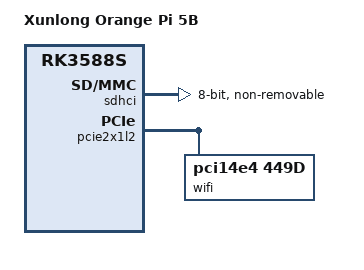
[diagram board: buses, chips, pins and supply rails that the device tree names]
// SPDX-License-Identifier: (GPL-2.0+ OR MIT)

/dts-v1/;

#include "rk3588s-orangepi-5.dts"

/ {
	model = "Xunlong Orange Pi 5B";
	compatible = "xunlong,orangepi-5b", "rockchip,rk3588s";

	aliases {
		mmc0 = &sdmmc;
		mmc1 = &sdhci;
	};
};

&sdhci {
	bus-width = <8>;
	no-sdio;
	no-sd;
	non-removable;
	/* HS400 doesn't work properly -> https://github.com/torvalds/linux/commit/cee572756aa2cb46e959e9797ad4b730b78a050b */
	mmc-hs200-1_8v;
	max-frequency = <200000000>;
	status = "okay";
};

&sfc {
	status = "disabled";
};

&pcie2x1l2 {
	pcie@0,0 {
		reg = <0x400000 0 0 0 0>;
		#address-cells = <3>;
		#size-cells = <2>;
		ranges;
		device_type = "pci";
		bus-range = <0x40 0x4f>;

		wifi: wifi@0,0 {
			compatible = "pci14e4,449d";
			reg = <0x410000 0 0 0 0>;
			clocks = <&hym8563>;
			clock-names = "32k";
		};
	};
};
